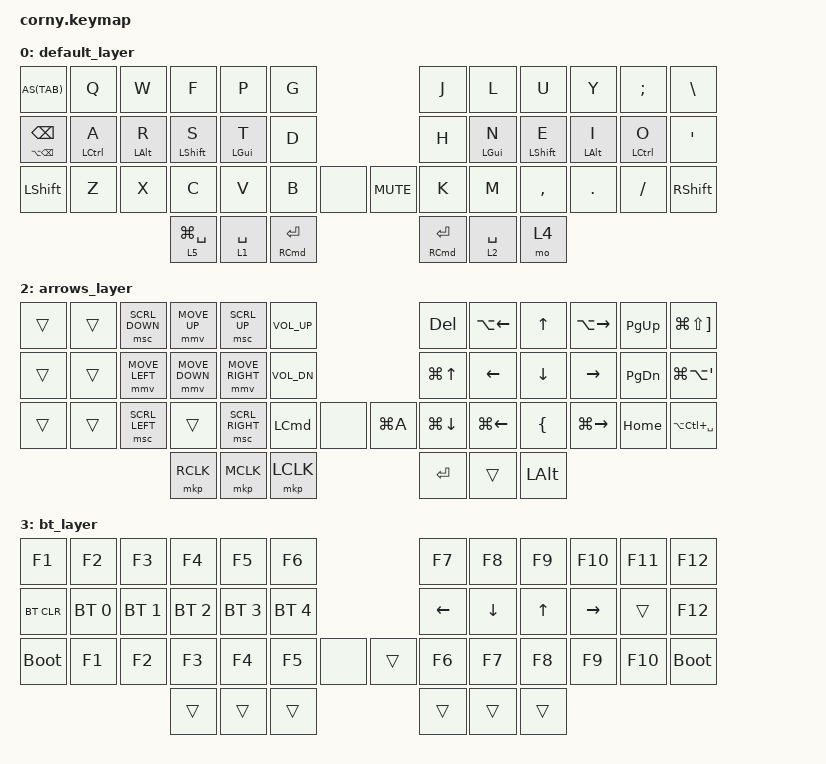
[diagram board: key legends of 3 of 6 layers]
#define ZMK_POINTING_DEFAULT_MOVE_VAL 1500  // default: 600
#define ZMK_POINTING_DEFAULT_SCRL_VAL 20    // default: 10
#include <dt-bindings/zmk/pointing.h>
#include <behaviors.dtsi>
#include <behaviors/mouse_keys.dtsi>
#include <dt-bindings/zmk/bt.h>
#include <dt-bindings/zmk/keys.h>
#define AS(keycode) &as LS(keycode) keycode             // Autoshift 
//#define DT(keycode) &dt keycode keycode                 // Double Tap
#define BCK &bck_ht LA(BACKSPACE) BACKSPACE             // BackSpace
#define IT_E &it_e 0
#define COMBOMS 30
#define HOLDTAP 165 // Old Value 150
#define MACRO_WAIT_TIME 25


/ {
//MACROS
        macros {
                it_egrav: it_egrav {
                        compatible = "zmk,behavior-macro";
                        #binding-cells = <0>;
                        bindings
                                = <&kp LC(LA(LG(I)))>,
                                <&macro_wait_time MACRO_WAIT_TIME>,
                                <&kp LBKT>,
                                <&macro_wait_time MACRO_WAIT_TIME>,
                                <&kp LC(LA(LG(E)))>;
                };
                it_shift_egrav: it_shift_egrav {
                        compatible = "zmk,behavior-macro";
                        #binding-cells = <0>;
                        bindings
                                = <&kp LC(LA(LG(I)))>,
                                <&macro_wait_time MACRO_WAIT_TIME>,
                                <&kp LS(LBKT)>,
                                <&macro_wait_time MACRO_WAIT_TIME>,
                                <&kp LC(LA(LG(E)))>;
                };
                it_i: it_i {
                        compatible = "zmk,behavior-macro";
                        #binding-cells = <0>;
                        bindings
                                = <&kp LC(LA(LG(I)))>,
                                <&macro_wait_time MACRO_WAIT_TIME>,
                                <&kp EQUAL>,
                                <&macro_wait_time MACRO_WAIT_TIME>,
                                <&kp LC(LA(LG(E)))>;
                };
                it_o: it_o {
                        compatible = "zmk,behavior-macro";
                        #binding-cells = <0>;
                        bindings
                                = <&kp LC(LA(LG(I)))>,
                                <&macro_wait_time MACRO_WAIT_TIME>,
                                <&kp SEMI>, 
                                <&macro_wait_time MACRO_WAIT_TIME>,
                                <&kp LC(LA(LG(E)))>;
                };
                it_u: it_u {
                        compatible = "zmk,behavior-macro";
                        #binding-cells = <0>;
                        bindings
                                = <&kp LC(LA(LG(I)))>,
                                <&macro_wait_time MACRO_WAIT_TIME>,
                                <&kp BSLH>,
                                <&macro_wait_time MACRO_WAIT_TIME>,
                                <&kp LC(LA(LG(E)))>;
                };
                it_a: it_a {
                        compatible = "zmk,behavior-macro";
                        #binding-cells = <0>;
                        bindings 
                                = <&kp LC(LA(LG(I)))>,
                                <&macro_wait_time MACRO_WAIT_TIME>,
                                <&kp SQT>,
                                <&macro_wait_time MACRO_WAIT_TIME>,
                                <&kp LC(LA(LG(E)))>;
                };
                efp: efp {
                        compatible = "zmk,behavior-macro";
                        #binding-cells = <0>;
                        bindings = <&kp UNDERSCORE &kp F &kp P>,
                                <&macro_wait_time MACRO_WAIT_TIME>;
                };
                elaugh: elaugh {
                        compatible = "zmk,behavior-macro";
                        #binding-cells = <0>;
                        bindings = <&kp UNDERSCORE &kp L &kp A>,
                                <&macro_wait_time MACRO_WAIT_TIME>;     
                };
                eok: eok {
                        compatible = "zmk,behavior-macro";
                        #binding-cells = <0>;
                        bindings = <&kp UNDERSCORE &kp O &kp K>,
                                <&macro_wait_time MACRO_WAIT_TIME>;     
                };
                ethank: ethank {
                        compatible = "zmk,behavior-macro";
                        #binding-cells = <0>;
                        bindings = <&kp UNDERSCORE &kp T &kp H>,
                                <&macro_wait_time MACRO_WAIT_TIME>;
                };
                esmile: esmile {
                        compatible = "zmk,behavior-macro";
                        #binding-cells = <0>;
                        bindings = <&kp UNDERSCORE &kp S &kp M>,
                                <&macro_wait_time MACRO_WAIT_TIME>;
                };
                esad: esad {
                        compatible = "zmk,behavior-macro";
                        #binding-cells = <0>;
                        bindings = <&kp UNDERSCORE &kp S &kp A &kp D>,
                                <&macro_wait_time MACRO_WAIT_TIME>;
                };
                elove: elove {
                        compatible = "zmk,behavior-macro";
                        #binding-cells = <0>;
                        bindings = <&kp UNDERSCORE &kp L &kp V>,
                                <&macro_wait_time MACRO_WAIT_TIME>;
                };
                ehmmm: ehmmm {
                        compatible = "zmk,behavior-macro";
                        #binding-cells = <0>;
                        bindings = <&kp UNDERSCORE &kp H &kp M>,
                                <&macro_wait_time MACRO_WAIT_TIME>;
                };
                ecoffe: ecoffe {
                        compatible = "zmk,behavior-macro";
                        #binding-cells = <0>;
                        bindings = <&kp UNDERSCORE &kp C &kp F>,
                                <&macro_wait_time MACRO_WAIT_TIME>;
                };
                //double cmd and ctrl Press
                doublecmd: doublecmd{
                        compatible = "zmk,behavior-macro";
                        #binding-cells = <0>;
                        bindings = <&kp LCMD &kp LCMD>,
                                <&macro_wait_time MACRO_WAIT_TIME>;
                };
                doublectrl: doublectrl{
                        compatible = "zmk,behavior-macro";
                        #binding-cells = <0>;
                        bindings = <&kp LCTRL &kp LCTRL>,
                                <&macro_wait_time MACRO_WAIT_TIME>;
                };
        };

//COMBOS
        combos {
                compatible = "zmk,combos";
                // //Left CMD - ST
                // combo_lcmd {
                //         timeout-ms = <COMBOMS>;
                //         key-positions = <15 16>;
                //         bindings = <&kp LCMD>;
                // };
                // //Right CMD - NE
                // combo_rcmd {
                //         timeout-ms = <COMBOMS>;
                //         key-positions = <19 20>;
                //         bindings = <&kp LCMD>;
                // };
                // //Left ALT - RS
                // combo_lalt {
                //         timeout-ms = <COMBOMS>;
                //         key-positions = <13 14>;
                //         bindings = <&kp LALT>;
                // };
                // //Right ALT - EI
                // combo_ralt {
                //         timeout-ms = <COMBOMS>;
                //         key-positions = <21 22>;
                //         bindings = <&kp LALT>;
                // };
                // //Left CTRL - AR
                // combo_lctrl {
                //         timeout-ms = <COMBOMS>;
                //         key-positions = <14 15>;
                //         bindings = <&kp LCTRL>;
                // };
                // //Right CTRL - IO
                // combo_rctrl {
                //         timeout-ms = <COMBOMS>;
                //         key-positions = <20 21>;
                //         bindings = <&kp LCTRL>;
                // };
                //MEH and Hyper
                                // //Left MEH - RST - 13 14 15
                                // combo_lmeh {
                                //         timeout-ms = <COMBOMS>;
                                //         key-positions = <14 15 16>;
                                //         bindings = <&kp LC(LA(LEFT_SHIFT))>;
                                // };
                                // //Right MEH - NEI - 19 20 21
                                // combo_rmeh {
                                //         timeout-ms = <COMBOMS>;
                                //         key-positions = <19 20 21>;
                                //         bindings = <&kp RC(RA(RIGHT_SHIFT))>;
                                // }; 
                                // //Left Hyper - ARST - 13 14 15 16
                                // combo_lhyp {
                                //         timeout-ms = <COMBOMS>;
                                //         key-positions = <13 14 15 16>;
                                //         bindings = <&kp LC(LA(LG(LEFT_SHIFT)))>;
                                // };
                                // //Rihgt Hyper - NEIO - 19 20 21 22
                                // combo_rhyp {
                                //         timeout-ms = <COMBOMS>;
                                //         key-positions = <19 20 21 22>;
                                //         bindings = <&kp RC(RA(RG(RIGHT_SHIFT)))>;
                                // };
                //Escape - WF
                combo_esc {
                        timeout-ms = <COMBOMS>;
                        key-positions = <2 3>;
                        bindings = <&kp ESC>;
                };
                //DEL - FP
                combo_del {
                        timeout-ms= <50>;
                        key-positions = <3 4>; 
                        bindings = <&kp DEL>;
                };
        };

//Behaivors
        behaviors {
        // BackSpace HOLD Tap 
                bck_ht: bck_ht {
                        compatible = "zmk,behavior-hold-tap";
                        bindings = <&kp>, <&kp>;
                        #binding-cells = <2>;
                        tapping-term-ms = <145>;    
                        quick-tap-ms = <0>;
                        require-prior-idle-ms = <140>; //initial value 140
                        flavor = "balanced";
                };
        // Hold Tap General
                ht: ht {
                        compatible = "zmk,behavior-hold-tap";
                        bindings = <&kp>, <&kp>;
                        #binding-cells = <2>;
                        tapping-term-ms = <HOLDTAP>;    
                        quick-tap-ms = <50>;
                        require-prior-idle-ms = <50>; //initial value 140
                        flavor = "balanced";
                };
        // IT_E Hold Tap
                it_e: it_e {
                        compatible = "zmk,behavior-hold-tap";
                        #binding-cells = <2>;
                        tapping-term-ms = <HOLDTAP>;
                        quick-tap-ms = <50>; // 50 I think is the sweet Spot for this settings
                        require-prior-idle-ms = <50>; // 50 I think this is the sweet spot for this settings
                        flavor = "balanced";
                        bindings = <&it_shift_egrav>, <&it_egrav>;
                };
        // Autoshift Hold Tap
                as: auto_shift {
                        compatible = "zmk,behavior-hold-tap";
                        label = "ZM_autoshift";
                        #binding-cells = <2>;
                        tapping-term-ms = <170>; //prev was 140 HOLDTAP=165 at the moment
                        //quick-tap-ms = <50>; // 50 I think is the sweet Spot for this settings
                        //require-prior-idle-ms = <50>; // 50 I think this is the sweet spot for this settings
                        flavor = "hold-preferred"; // balanced
                        bindings = <&kp &kp>;
                };
        // Capture Screen Key TAP Dance
                mk_capt: tap_dance_mod_tap {
                        compatible = "zmk,behavior-tap-dance"; 
                        #binding-cells = <0>;
                        tapping-term-ms = <HOLDTAP>; //old 200
                        bindings = <&mt LG(LC(LS(N4)))  LG(LS(N2))>, <&mt LG(LS(N5))  LG(LS(N4))>;
                };
      // Home Row
                hm: hm {
                        compatible = "zmk,behavior-hold-tap";
                        #binding-cells = <2>;
                        tapping-term-ms = <160>;
                        quick-tap-ms = <50>;
                        flavor = "balanced";
                        require-prior-idle-ms = <100>;
                        bindings = <&kp>, <&kp>;
                };        
        // Tap Dance Amethyst Full Screen window Mode and 2 panes
                dt_ameth: dt_ameth {
                        compatible = "zmk,behavior-tap-dance";
                        #binding-cells = <0>;
                        tapping-term-ms = <HOLDTAP>; //old 200
                        bindings = <&kp LA(LS(O))>, <&kp LA(LS(D))>,  <&kp LA(LS(J))>;
                };
        // Double Tap for Layer 4 and HT CMD and Tap Enter
                // tap_layer4:tap_layer4 {
                //         compatible = "zmk,behavior-tap-dance";
                //         #binding-cells = <0>;
                //         tapping-term-ms =<140>;
                //         bindings = <&lt 2 SPACE>, <&mo 4>; 
                //                         // bindings = <&ht RCMD RET>, <&mo 4>;
                // };
           // Double Tap for Layer 5 Emoji and HT CMD and Tap Enter
                // tap_layer5:tap_layer5 {
                //         compatible = "zmk,behavior-tap-dance";
                //         #binding-cells = <0>;
                //         tapping-term-ms = <140>;//old was hold tap
                //         bindings = <&ht RCMD RET>, <&mo 5>;
                // };
        };

        conditional_layers {
                compatible = "zmk,conditional-layers";
                tri_layer {
                        if-layers = <1 2>;
                        then-layer = <3>;
                };
        };

        keymap {
                compatible = "zmk,keymap";

//Layer 0 - Default
                default_layer {
        // -------------------------------------------------------------------------------------------------
        // |  TAB      |  Q  |  W  |  E  |  R  |  T  |                      |  Y  |  U   |  I  |  O  |  P  |   \  |
        // | Bakcspace |  A  |  S  |  D  |  F  |  G  |                      |  H  |  J   |  K  |  L  |  ;  |   '  |
        // | SHFT      |  Z  |  X  |  C  |  V  |  B  |  None|     |  MUTE   |  N  |  M   |  ,  |  .  |  /  | SHFT |
        //    4-WinMan+emoji  | 1-Numbers/Space | CMD/Enter |  | CMD/Enter | 2-Arrows  | 3-Italian Accents |
        //                                              Vol+    Vol-
        //LA(BACKSPACE) BACKSPACE AS(A)
                bindings = <
AS(TAB)    &kp Q        &kp W       &kp F        &kp P      &kp G                             &kp J  &kp L        &kp U        &kp Y        &kp SEMI      &kp BSLH
BCK        &hm LCTRL A  &hm LALT R  &hm LSHFT S  &hm LGUI T &kp D                             &kp H  &hm LGUI N   &hm LSHFT E  &hm LALT I   &hm LCTRL O   &kp SQT
&kp LSHFT  &kp Z        &kp X       &kp C        &kp V      &kp B      &none   &kp C_MUTE     &kp K  &kp M        &kp COMMA    &kp DOT      &kp SLASH     &kp RSHFT
                                  &lt 5 LG(SPACE)  &lt 1 SPACE  &ht RCMD RET             &ht RCMD RET   &lt 2 SPACE  &mo 4
                        >;
                        sensor-bindings = <&inc_dec_kp C_VOL_UP C_VOL_DN>;
                };

//Layer 1 Numbers____________________________________________________________________________________________________________________________________
                numbers_layer {
                        bindings = <
&trans     &kp EXCL      &kp AT_SIGN  &kp POUND      &kp DOLLAR     &kp PERCENT                                 &kp CARET  &kp AMPS      &kp STAR      &kp LEFT_PARENTHESIS  &kp RIGHT_PARENTHESIS   &kp CAPS
&trans     &hm LCTRL N1  &hm LALT N2  &hm LSHFT N3   &hm LGUI N4    &kp N5                                      &kp N6     &hm LGUI N7   &hm LSHFT N8  &hm LALT N9           &hm LCTRL N0            AS(EQUAL)
&mk_capt   &kp LBKT      &kp RBKT     &kp LC(LEFT)   &kp LC(RIGHT)  &dt_ameth   &none    &kp LC(LA(LS(Z)))      &kp PLUS   AS(MINUS)     &trans        &trans                &trans                  AS(GRAVE)
                                                &kp LA(LS(B))      &trans      &trans          &trans     &trans     &trans
                        >;
                        sensor-bindings = <&inc_dec_kp C_BRI_INC C_BRI_DEC>;
                }; 

//Layer 2  Arrows Mouse __________________________________________________________________________________________________________________________________________ 
        // --------------------------------------------------------------------------------------------------------
        // |  TAB      |  Q  |  W  |  E  |  R  |  T  |                      |  Y  |  U   |  I  |  O  |  P  | Omnifocus new Child      |
        // | Bakcspace |  A  |  S  |  D  |  F  |  G  |                      |  H  |  J   |  K  |  L  |  ;  | Omnifocus show/hide Note |
        // | SHFT      |  Z  |  X  |  C  |  V  |  B  |  None|     |  MUTE   |  N  |  M   |  ,  |  .  |  /  | Omnifocus New Task       |
        //    4-WinMan+emoji  | 1-Numbers/Space | CMD/Enter |  | CMD/Enter | 2-Arrows  | 3-Italian Accents |
        //                                              Vol+    Vol-
        //LA(BACKSPACE) BACKSPACE AS(A)
                arrows_layer {
                        bindings = <
&trans   &trans   &msc SCRL_DOWN   &mmv MOVE_UP     &msc SCRL_UP       &kp C_VOL_UP                       &kp DEL      &kp LA(LEFT)  &kp UP   &kp LA(RIGHT)  &kp PG_UP  &kp LG(LS(RBKT))
&trans   &trans   &mmv MOVE_LEFT   &mmv MOVE_DOWN   &mmv MOVE_RIGHT    &kp C_VOL_DN                       &kp LG(UP)   &kp LEFT      &kp DOWN &kp RIGHT      &kp PG_DN  &kp LG(LA(SQT))  
&trans   &trans   &msc SCRL_LEFT   &trans           &msc SCRL_RIGHT    &kp LCMD        &none   &kp LG(A)  &kp LG(DOWN) &kp LG(LEFT)  &kp LBRC &kp LG(RIGHT)  &kp HOME   &kp LA(LC(SPACE))
                            &mkp RCLK  &mkp MCLK     &mkp LCLK                                  &kp RET   &trans    &kp LALT
                        >;
                        sensor-bindings = <&inc_dec_kp UP DOWN>;
                };

//Layer 3  Bluetooth System Layer______________________________________________________________________________________________________________________________
                bt_layer {
                        bindings = <
        &kp F1        &kp F2        &kp F3        &kp F4        &kp F5        &kp F6                           &kp F7     &kp F8   &kp F9   &kp F10    &kp F11  &kp F12
        &bt BT_CLR    &bt BT_SEL 0  &bt BT_SEL 1  &bt BT_SEL 2  &bt BT_SEL 3  &bt BT_SEL 4                     &kp LEFT   &kp DOWN &kp UP   &kp RIGHT  &trans   &kp F12
        &bootloader   &kp F1        &kp F2        &kp F3        &kp F4        &kp F5        &none   &trans     &kp F6     &kp F7   &kp F8   &kp F9     &kp F10  &bootloader
                                                                        &trans   &trans   &trans        &trans   &trans   &trans
                        >;
                        sensor-bindings = <&inc_dec_kp LEFT RIGHT>;
                };

// 
//Layer 4 Italian Accents_______________________________________________________________________________________________________________________________________
                it_layer {
                        bindings = <
        &kp C_PREV      &kp C_PLAY_PAUSE      &kp C_NEXT      &kp K_MUTE      &kp K_VOL_DN     &kp K_VOL_UP                                 &trans          &trans         &it_u           &trans           &trans            &trans
        &trans          &it_a                 &trans          &trans          &kp C_BRI_DEC    &kp C_BRI_INC                                       &trans          &trans         IT_E            &trans           &it_i             &it_o              &none
        &ht LG(N1) F1   &ht LG(N2) F2         &ht LG(N3) F3   &ht LG(N4) F4   &ht LG(N5) F5    &ht LG(N6) F6    &none   &kp LC(LA(LS(D)))   &ht LG(N7) F7   &ht LG(N8) F8  &ht LG(N9) F9   &ht LG(N0) F10   &ht LG(Z) F11    &ht LG(LS(Z)) F12
                                                          &trans   &trans   &trans                                                                         &trans   &trans   &trans
                                >;
                        sensor-bindings = <&inc_dec_kp LC(LG(LA(LS(F)))) LC(LG(LA(LS(R))))>; 
                };
        
//Layer 5 Emoji and Window Manip_________________________________________________________________________________________________________________________________
                emoji_layer {
                        bindings = <
        &trans   &trans    &elove   &efp          &ehmmm          &ecoffe                                         &trans   &trans     &trans     &trans    &trans    &trans
        &trans   &elaugh   &esmile  &eok          &ethank         &esad                                           &trans   &trans     &trans     &trans    &trans    &trans
        &trans   &trans    &trans   &doublecmd    &doublectrl     &trans      &none   &kp LC(LG(LA(LS((P)))))     &trans   &trans     &trans     &trans    &trans    &trans
                                                        &trans      &trans      &trans                              &trans   &trans     &trans
                                >;
                        sensor-bindings = <&inc_dec_kp LC(LG(LA(LS((M))))) LC(LG(LA(LS((N)))))>;
                };
        };
};


// &ht LG(N1) F1   &ht LG(N2) F2  &ht LG(N3) F3   &ht LG(N4) F4   &ht LG(N5) F5    &ht LG(N6) F6     &none  &trans      &ht LG(N7) F7   &ht LG(N8) F8  &ht LG(N9) F9   &ht LG(N10) F10   &ht LG(N11) F11    &ht LG(N12) F12

        // &trans   &trans   &trans   &trans   &trans   &trans                          &trans   &trans   &trans   &trans   &trans   &trans
        // &trans   &trans   &trans   &trans   &trans   &trans                          &trans   &trans   &trans   &trans   &trans   &trans
        // &trans   &trans   &trans   &trans   &trans   &trans   &none &bootloader      &trans   &trans   &trans   &trans   &trans   &trans
        //                                 &trans   &trans   &trans                                 &trans   &trans   &trans   


//   

// _lv 🥰     _hm 🤔    _cf ☕️      &elove     &ehmmm      &ecoffe 🤦‍♂️😂😁👍🙏😔🥰🤔☕️☕️☕️_☕️cfq☕️qq     🤔🥰🥰🤦‍♂️🤔😂😁👍😔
